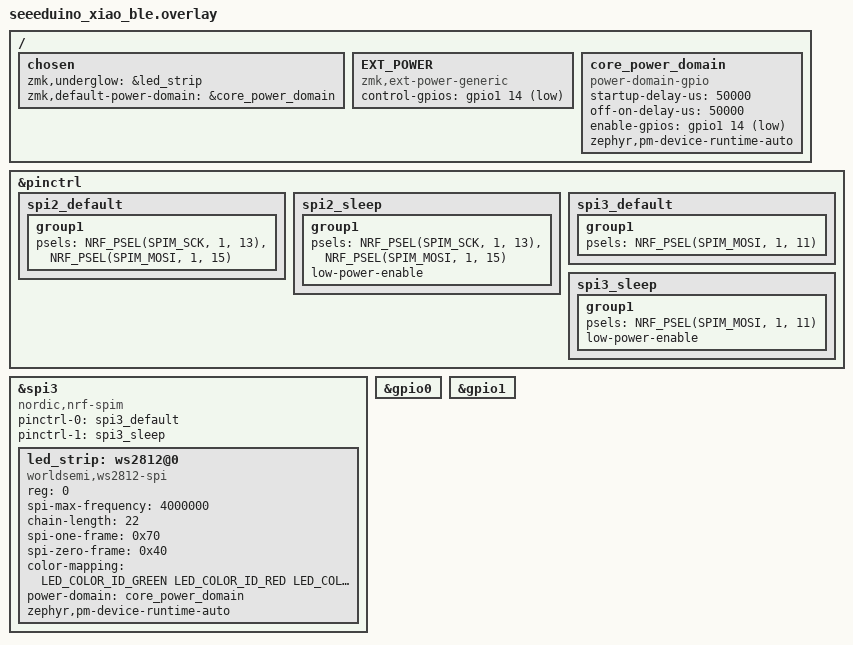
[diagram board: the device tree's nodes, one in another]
/*
 * Copyright (c) 2024 The ZMK Contributors
 * SPDX-License-Identifier: MIT
 */

#include <dt-bindings/led/led.h>

&pinctrl {
    spi2_default: spi2_default {
        group1 {
            psels = <NRF_PSEL(SPIM_SCK, 1, 13)>,
                <NRF_PSEL(SPIM_MOSI, 1, 15)>;
        };
    };

    spi2_sleep: spi2_sleep {
        group1 {
            psels = <NRF_PSEL(SPIM_SCK, 1, 13)>,
                <NRF_PSEL(SPIM_MOSI, 1, 15)>;
            low-power-enable;
        };
    };

    spi3_default: spi3_default {
        group1 {
            psels = <NRF_PSEL(SPIM_MOSI, 1, 11)>;
        };
    };
    spi3_sleep: spi3_sleep {
        group1 {
            psels = <NRF_PSEL(SPIM_MOSI, 1, 11)>;
            low-power-enable;
        };
    };
};

&spi3 {
    compatible = "nordic,nrf-spim";
    status = "okay";

    pinctrl-0 = <&spi3_default>;
    pinctrl-1 = <&spi3_sleep>;
    pinctrl-names = "default", "sleep";

    led_strip: ws2812@0 {
        compatible = "worldsemi,ws2812-spi";

        /* SPI */
        reg = <0>; /* ignored, but necessary for SPI bindings */
        spi-max-frequency = <4000000>;

        /* WS2812 */
        chain-length = <22>; /* The number of RGB LEDs per side. */
        spi-one-frame = <0x70>;
        spi-zero-frame = <0x40>;

        color-mapping = <LED_COLOR_ID_GREEN LED_COLOR_ID_RED LED_COLOR_ID_BLUE>;

        power-domain = <&core_power_domain>;
        zephyr,pm-device-runtime-auto;
    };
};

&gpio0 {
    status = "okay";
};

&gpio1 {
    status = "okay";
};

/ {
    chosen {
        zmk,underglow = &led_strip;
        zmk,default-power-domain = &core_power_domain;
    };

    EXT_POWER {
        compatible = "zmk,ext-power-generic";
        control-gpios = <&gpio1 14 GPIO_ACTIVE_LOW>;
    };

    core_power_domain: core_power_domain {
        compatible = "power-domain-gpio", "power-domain";
        startup-delay-us = <50000>;
        off-on-delay-us = <50000>;
        enable-gpios = <&gpio1 14 GPIO_ACTIVE_LOW>;
        zephyr,pm-device-runtime-auto;
    };
};
